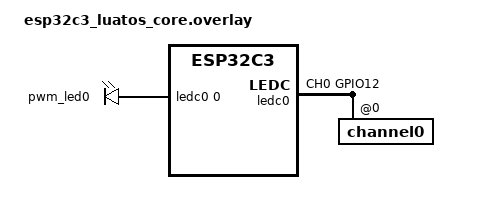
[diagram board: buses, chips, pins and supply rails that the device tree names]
/ {
    pwmleds {
        compatible = "pwm-leds";
        pwm_led0: pwm_led0 {
            pwms = <&ledc0 0 10000 0>;
        };
    };
};
//3456789012345678901234567890123456
&ledc0 {
    status = "okay";
    pinctrl-0 = <&ledc0_default>;
    pinctrl-names = "default";
    #address-cells = <1>;
    #size-cells = <0>;
    channel0@0 {
        reg = <0x0>;
        timer = <0>;
    };
};


&pinctrl {
    ledc0_default: ledc0_default {
        group1 {
            pinmux = <LEDC_CH0_GPIO12>;
            output-enable;
        };
    };
};



                                    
